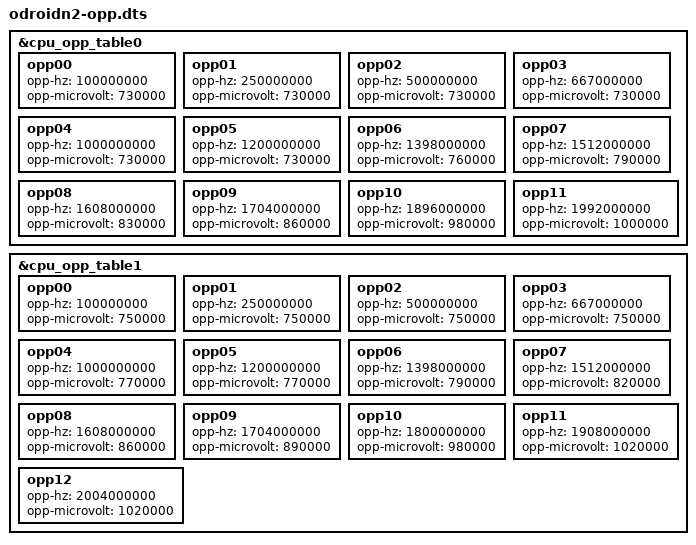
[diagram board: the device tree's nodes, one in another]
// cpu opp table
/dts-v1/;
/plugin/;

/{
	fragment@0 {
		target= <&cpu_opp_table0>;

		__overlay__ {
			opp00 {
				opp-hz = /bits/ 64 <100000000>;
				opp-microvolt = <730000>;
			};
			opp01 {
				opp-hz = /bits/ 64 <250000000>;
				opp-microvolt = <730000>;
			};
			opp02 {
				opp-hz = /bits/ 64 <500000000>;
				opp-microvolt = <730000>;
			};
			opp03 {
				opp-hz = /bits/ 64 <667000000>;
				opp-microvolt = <730000>;
			};
			opp04 {
				opp-hz = /bits/ 64 <1000000000>;
				opp-microvolt = <730000>;
			};
			opp05 {
				opp-hz = /bits/ 64 <1200000000>;
				opp-microvolt = <730000>;
			};
			opp06 {
				opp-hz = /bits/ 64 <1398000000>;
				opp-microvolt = <760000>;
			};
			opp07 {
				opp-hz = /bits/ 64 <1512000000>;
				opp-microvolt = <790000>;
			};
			opp08 {
				opp-hz = /bits/ 64 <1608000000>;
				opp-microvolt = <830000>;
			};
			opp09 {
				opp-hz = /bits/ 64 <1704000000>;
				opp-microvolt = <860000>;
			};
			opp10 {
				opp-hz = /bits/ 64 <1896000000>;
				opp-microvolt = <980000>;
			};
			opp11 {
				opp-hz = /bits/ 64 <1992000000>;
				opp-microvolt = <1000000>;
			};
		};
	};
	fragment@1 {
		target= <&cpu_opp_table1>;

		__overlay__ {
			opp00 {
				opp-hz = /bits/ 64 <100000000>;
				opp-microvolt = <750000>;
			};
			opp01 {
				opp-hz = /bits/ 64 <250000000>;
				opp-microvolt = <750000>;
			};
			opp02 {
				opp-hz = /bits/ 64 <500000000>;
				opp-microvolt = <750000>;
			};
			opp03 {
				opp-hz = /bits/ 64 <667000000>;
				opp-microvolt = <750000>;
			};
			opp04 {
				opp-hz = /bits/ 64 <1000000000>;
				opp-microvolt = <770000>;
			};
			opp05 {
				opp-hz = /bits/ 64 <1200000000>;
				opp-microvolt = <770000>;
			};
			opp06 {
				opp-hz = /bits/ 64 <1398000000>;
				opp-microvolt = <790000>;
			};
			opp07 {
				opp-hz = /bits/ 64 <1512000000>;
				opp-microvolt = <820000>;
			};
			opp08 {
				opp-hz = /bits/ 64 <1608000000>;
				opp-microvolt = <860000>;
			};
			opp09 {
				opp-hz = /bits/ 64 <1704000000>;
				opp-microvolt = <890000>;
			};
			opp10 {
				opp-hz = /bits/ 64 <1800000000>;
				opp-microvolt = <980000>;
			};
			opp11 {
				opp-hz = /bits/ 64 <1908000000>;
				opp-microvolt = <1020000>;
			};
			opp12 {
				opp-hz = /bits/ 64 <2004000000>;
				opp-microvolt = <1020000>;
			};
		};
	};
};
